# TLE985x register map
Vendor: Infineon Technologies AG; Series: MOTIX MCU; File version: 1.6
SVD file
CPU: CM0 r0p0, little endian, no MPU, no FPU, 2 interrupt priority bits
Registers are 32-bit, read-write, no defined reset value unless marked. A register's access mark holds for its fields unless they carry their own. Offsets are from the block's base; lines under a group give offsets from that group; [hi:lo] are bit positions; {n}, {i} and the like mark numbered series; 'fields as' and 'values as' point back to an identical list; <NAME> marks a mode.

## Memory map
0x40004000 ADC1 size 0x4000
0x4000C000 CCU6 size 0x4000
0x40010000 GPT12E size 0x4000
0x40024000 HS size 0x4000
0x40034000 BDRV size 0x4000
0x48004000 TIMER2 size 0x1000
0x48005000 TIMER21 size 0x1000
0x48013000 MATH size 0x1000
0x48018000 MF size 0x4000
0x4801C000 ADC2 size 0x2000
0x4801E000 LIN size 0x2000
0x48020000 UART1 size 0x2000
0x48022000 UART2 size 0x2000
0x48024000 SSC1 size 0x2000
0x48026000 SSC2 size 0x2000
0x48028000 PORT size 0x2000
0x50004000 PMU size 0x1000
0x50005000 SCU size 0x1000
0x50006000 SCUPM size 0x1000
0xE000E000 CPU size 0x1000

## Interrupts
0 INTISR0 (GPT12E) — Interrupt node 0: GPT1 Block
1 INTISR1 (GPT12E) — Interrupt node 1: GPT2 Block
2 INTISR2 (ADC2) — Interrupt node 2: ADC2, Timer3
3 INTISR3 (ADC1) — Interrupt node 3: ADC1
4 INTISR4 (CCU6) — Interrupt node 4: CCU6 node0
5 INTISR5 (CCU6) — Interrupt node 5: CCU6 node1
6 INTISR6 (CCU6) — Interrupt node 6: CCU6 node2
7 INTISR7 (CCU6) — Interrupt node 7: CCU6 node3
8 INTISR8 (SSC1) — Interrupt node 8: SSC1
9 INTISR9 (SSC2) — Interrupt node 9: SSC2
10 INTISR10 (UART1) — Interrupt node 10: UART1(ASC,LIN), Timer2
11 INTISR11 (UART2) — Interrupt node 11: UART2, Timer21
12 INTISR12 (SCU) — Interrupt node 12: EINT0
13 INTISR13 (SCU) — Interrupt node 13: EINT1
14 INTISR14 (PMU) — Interrupt node 14: Wakeup
15 INTISR15 (MATH) — Interrupt node 15: Math Div
17 INTISR17 (BDRV) — Interrupt node 17: BDRV LS1, OC, OT, OL
18 INTISR18 (BDRV) — Interrupt node 18: BDRV LS2, OC, OT, OL
19 INTISR19 (BDRV) — Interrupt node 19: BDRV HS1, OC, OT, OL
20 INTISR20 (BDRV) — Interrupt node 20: BDRV HS2, OC, OT, OL
21 INTISR21 (ADC1) — Interrupt node 21: Differential Unit
22 INTISR22 (PMU) — Interrupt node 22: MONx
23 INTISR23 (PORT) — Interrupt node 23: Port 2.x (ADC1)

## HS
Base 0x40024000
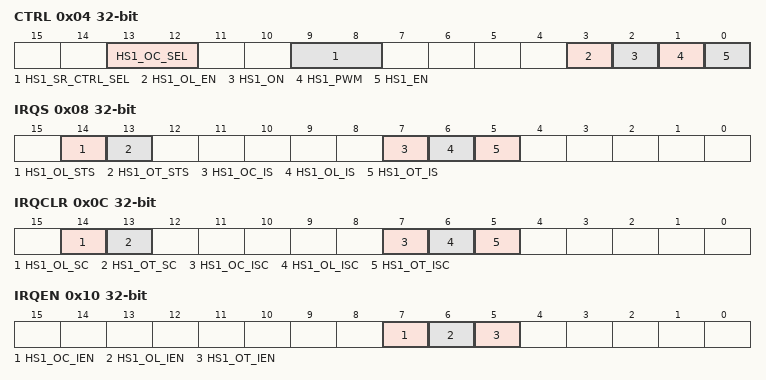
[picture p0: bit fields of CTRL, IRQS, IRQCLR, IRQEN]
0x04 CTRL — High Side Driver Control
  [13:12] HS1_OC_SEL — High Side 1 Overcurrent Threshold Selection
    0=IOCTH0 (25 mA min.); 1=IOCTH1 (50 mA min.); 2=IOCTH2 (100 mA min.); 3=IOCTH3 (150 mA min.)
  [9:8] HS1_SR_CTRL_SEL — High Side 1 Slew Rate Control select
    0=Slew_Rate_1 (Slow Slew Rate 3V/us is enabled); 1=Slew_Rate_2 (Fast Slew Rate 40V/us is enabled); 2=Slew_Rate_3 (Low EMC Slew Rate 1V/us is enabled (for low EMC emissions))
  [3] HS1_OL_EN — High Side 1 Open Load Detection Enable
    0=DISABLE (disable open load detection); 1=ENABLE (enable open load detection)
  [2] HS1_ON — High Side 1 On
    0=OFF (HS driver off); 1=ON (HS driver on)
  [1] HS1_PWM — High Side 1 PWM Enable
    0=DISABLE (disables control by PWM input); 1=ENABLE (enables control by PWM input)
  [0] HS1_EN — High Side 1 Enable
    0=DISABLE (HS circuit power off); 1=ENABLE (HS circuit power on)
0x08 IRQS — High Side Driver Interrupt Status
  [14] HS1_OL_STS — High Side 1 Open Load Status
    0=no open load Condition occurred; 1=open load occurred; switch is not automatically shutdown. Write sets status.
  [13] HS1_OT_STS — High Side 1 Overtemperature Status
    0=no overtemperature occurred; 1=overtemperature occurred; switch is automatically shutdown. Write sets status.
  [7] HS1_OC_IS — High Side 1 Overcurrent Interrupt Status
    0=no overcurrent Condition occurred; 1=overcurrent occurred; switch is automatically shutdown. Write sets status.
  [6] HS1_OL_IS — High Side 1 Open Load Interrupt Status
    0=NORMAL (normal load); 1=OPEN_LOAD (open load detected, write sets status)
  [5] HS1_OT_IS — High Side 1 Overtemperature Interrupt Status
    0=no overtemperature occurred; 1=overtemperature occurred; switch is automatically shutdown. Write sets status
0x0C IRQCLR wo — High Side Driver Interrupt Status Clear Register
  [all] fields
    0=no_Clear; 1=Clear
  [14] HS1_OL_SC — High Side 1 Open Load Status Clear
  [13] HS1_OT_SC — High Side 1 Overtemperature Status Clear
  [7] HS1_OC_ISC — High Side 1 Overcurrent Interrupt Status Clear
  [6] HS1_OL_ISC — High Side 1 Open Load Interrupt Status Clear
  [5] HS1_OT_ISC — High Side 1 Overtemperature Interrupt Status Clear
0x10 IRQEN — High Side Driver Interrupt Enable Register
  [7] HS1_OC_IEN — High Side 1 Overcurrent Interrupt Enable
    0=disable; 1=enable
  [6] HS1_OL_IEN — High Side 1 Open Load Interrupt Enable
    0=disable; 1=enable
  [5] HS1_OT_IEN — High Side 1 Overtemperature Interrupt Enable
    0=disabled; 1=enable
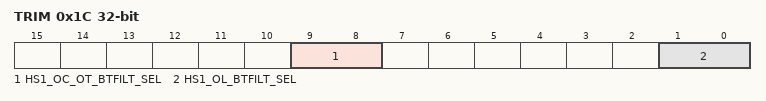
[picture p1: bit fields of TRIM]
0x1C TRIM — High Side Driver 1 TRIM
  [9:8] HS1_OC_OT_BTFILT_SEL — Blanking Time Filter Select for HS1 overcurrent / overtemperature detection
    0=4 us filter time; 1=8 us filter time; 2=16 us filter time; 3=32 us filter time
  [1:0] HS1_OL_BTFILT_SEL — Blanking Time Filter Select for HS1 open Load detection
    values as HS1_OC_OT_BTFILT_SEL
0x24 PWMSRCSEL — High Side PWM Source Selection Register
  [5:3] HS1_SRC_SEL — HS1 PWM Source Selection
    0=CC60 (PWM output of CCU6); 1=CC61 (PWM output of CCU6); 2=CC62 (PWM output of CCU6); 3=COUT60 (PWM output of CCU6); 4=COUT61 (PWM output of CCU6); 5=COUT62 (PWM output of CCU6); 6=T3OUT (PWM output of GPT12)
